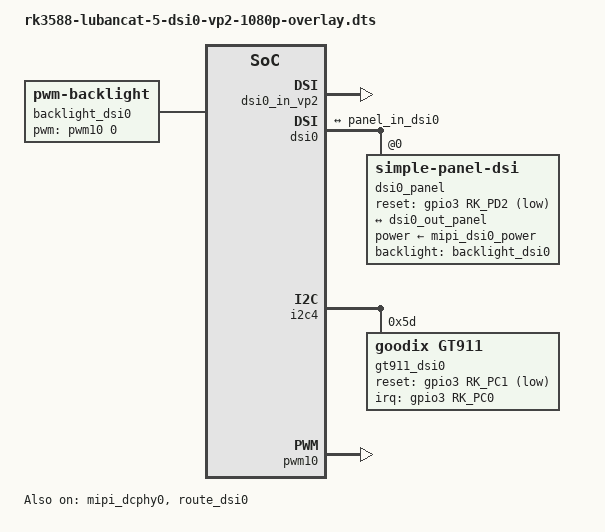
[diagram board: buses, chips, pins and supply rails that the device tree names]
/dts-v1/;
/plugin/;

#include <dt-bindings/gpio/gpio.h>
#include <dt-bindings/pinctrl/rockchip.h>
#include <dt-bindings/display/drm_mipi_dsi.h>
#include <dt-bindings/interrupt-controller/irq.h>

/ {
	fragment@0 {
		target = <&mipi_dcphy0>;

		__overlay__ {
			status = "okay";
		};
	};

	fragment@1 {
		target = <&route_dsi0>;

		__overlay__ {
			status = "okay";
			connect = <&vp2_out_dsi0>;
		};
	};

	fragment@2 {
		target = <&dsi0_in_vp2>;

		__overlay__ {
			status = "okay";
		};
	};


	fragment@3 {
		target = <&dsi0>;

		__overlay__ {
			status = "okay";
			#address-cells = <1>;
			#size-cells = <0>;

			dsi0_panel: panel@0 {
				status = "okay";
				compatible = "simple-panel-dsi";
				reg = <0>;
				backlight = <&backlight_dsi0>;
				power-supply = <&mipi_dsi0_power>;
				reset-gpios = <&gpio3 RK_PD2 GPIO_ACTIVE_LOW>;

				enable-delay-ms = <35>;
				prepare-delay-ms = <6>;
				reset-delay-ms = <10>;
				init-delay-ms = <50>;
				unprepare-delay-ms = <0>;
				disable-delay-ms = <20>;

				size,width = <74>;
				size,height = <133>;

				dsi,flags = <(MIPI_DSI_MODE_VIDEO | MIPI_DSI_MODE_VIDEO_BURST | MIPI_DSI_MODE_LPM | MIPI_DSI_MODE_NO_EOT_PACKET)>;
				dsi,format = <MIPI_DSI_FMT_RGB888>;
				dsi,lanes  = <4>;

				panel-init-sequence = [
					39 00 05 FF AA 55 A5 80
					15 00 02 6F 31
					15 00 02 FA 00
					39 00 05 FF AA 55 A5 00
					39 00 06 F0 55 AA 52 08 00
					15 00 02 B1 21
					39 00 03 B2 10 82
					39 00 03 B2 87 22
					39 00 04 B4 25 02 8C
					39 00 03 B5 0A 00
					39 00 04 B8 00 04 02
					39 00 0A B9 03 00 18 11 31 44 03 51 00
					39 00 03 BA 00 32
					39 00 03 BC 7F 00
					39 00 05 BD 00 B6 10 10
					39 00 03 C6 11 10
					39 00 06 F0 55 AA 52 08 01
					39 00 03 B1 11 11
					39 00 07 B2 0D 0D 0D 0D 0D 0D
					39 00 07 B3 19 23 19 23 19 23
					39 00 07 B6 15 14 15 14 15 14
					39 00 03 BC 5F 00
					39 00 03 BD 5F 00
					39 00 03 BE 00 DB
					15 00 02 CA 0F
					39 00 06 F0 55 AA 52 08 02
					39 00 0F B0 00 09 1B 28 33 3D 45 30 2D 32 31 47 56 56
					39 00 10 B1 4E 60 74 74 86 8E 9C 9C A5 AD B7 C2 CE DA FF
					39 00 0F B2 00 09 1B 28 33 3D 45 30 2D 32 31 47 56 56
					39 00 10 B3 4E 60 74 74 86 8E 9C 9C A5 AD B7 C2 CE DA FF
					39 00 0F B4 00 09 1B 28 33 3D 45 30 2D 32 31 47 56 56
					39 00 10 B5 4E 60 74 74 86 8E 9C 9C A5 AD B7 C2 CE DA FF
					39 00 0F B6 00 09 1B 28 33 3D 45 30 2D 32 31 47 56 56
					39 00 10 B7 4E 60 74 74 86 8E 9C 9C A5 AD B7 C2 CE DA FF
					39 00 0F B8 00 09 1B 28 33 3D 45 30 2D 32 31 47 56 56
					39 00 10 B9 4E 60 74 74 86 8E 9C 9C A5 AD B7 C2 CE DA FF
					39 00 0F BA 00 09 1B 28 33 3D 45 30 2D 32 31 47 56 56
					39 00 10 BB 4E 60 74 74 86 8E 9C 9C A5 AD B7 C2 CE DA FF
					39 00 06 F0 55 AA 52 08 03
					39 00 05 B0 00 00 00 00
					39 00 05 B1 03 00 00 03
					39 00 08 B2 00 00 64 00 64 05 02
					39 00 03 B4 00 08
					39 00 05 B5 12 28 06 06
					39 00 06 BA 31 00 00 00 03
					39 00 06 BB 31 00 00 00 03
					39 00 06 F0 55 AA 52 08 05
					39 00 04 B0 03 11 3F
					39 00 03 B2 06 60
					39 00 03 B3 10 33
					15 00 02 B4 26
					39 00 04 B5 06 20 00
					39 00 04 B6 86 E0 00
					39 00 06 BA 8E 00 00 A4 00
					39 00 06 BB 06 00 00 20 00
					39 00 06 BC 8E 00 00 A4 00
					39 00 06 BD 2E 00 00 A4 00
					39 00 06 BE 8E 00 00 A0 00
					39 00 06 BF 06 00 00 24 00
					15 00 02 C1 00
					39 00 03 C8 05 10
					39 00 03 C9 03 10
					39 00 04 D0 00 0A 02
					39 00 04 D1 00 0A 04
					15 00 02 EC 12
					15 00 02 ED 00
					39 00 03 EE 03 00
					39 00 06 B0 00 04 08 11 12
					39 00 06 B1 1F 15 16 1F 1F
					39 00 06 B2 1F 13 1F 1F 1F
					39 00 06 B3 1F 19 19 19 19
					39 00 06 B4 1B 1B 1B 1B 1D
					39 00 04 B5 1D 1D 1D
					39 00 06 B6 00 05 09 11 12
					39 00 06 B7 1F 15 16 1F 1F
					39 00 06 B8 1F 13 1F 1F 1F
					39 00 06 B9 1F 19 19 19 19
					39 00 06 BA 1B 1B 1B 1B 1D
					39 00 04 BB 1D 1D 1D
					39 00 06 C0 00 09 05 12 11
					39 00 06 C1 1F 15 16 1F 1F
					39 00 06 C2 1F 13 1F 1F 1F
					39 00 06 C3 1F 19 19 19 19
					39 00 06 C4 1B 1B 1B 1B 1D
					39 00 04 C5 1D 1D 1D
					39 00 06 C6 00 08 04 12 11
					39 00 06 C7 1F 15 16 1F 1F
					39 00 06 C8 1F 13 1F 1F 1F
					39 00 06 C9 1F 19 19 19 19
					39 00 06 CA 1B 1B 1B 1B 1D
					39 00 04 CB 1D 1D 1D
					39 00 04 D0 00 AA 0A
					15 00 02 35 00
					05 C8 01 11
					15 00 02 FF 00 //CMD page select
					15 00 02 34 00 //SET_TEAR_OFF
					15 00 02 35 00 //SET_TEAR_ON
					05 C8 01 29
				];

				panel-exit-sequence = [
					05 78 01 28
					05 00 01 10
				];

				disp0_timings0: display-timings {
					native-mode = <&dsi0_timing0>;
					dsi0_timing0: timing0 {
						clock-frequency = <230163000>;
						hactive = <1440>;
						vactive = <2560>;
						hsync-len = <2>;
						hback-porch = <26>;
						hfront-porch = <20>;
						vsync-len = <2>;
						vback-porch = <8>;
						vfront-porch = <8>;
						hsync-active = <0>;
						vsync-active = <0>;
						de-active = <0>;
						pixelclk-active = <0>;
					};
				};

				ports {
					#address-cells = <1>;
					#size-cells = <0>;
					port@0 {
						reg = <0>;
						panel_in_dsi0: endpoint {
							remote-endpoint = <&dsi0_out_panel>;
						};
					};
				};
			};

			ports {
				#address-cells = <1>;
				#size-cells = <0>;

				port@1 {
					reg = <1>;
					dsi0_out_panel: endpoint {
						remote-endpoint = <&panel_in_dsi0>;
					};
				};
			};
		};
	};

	fragment@4 {
		target = <&i2c4>;

		__overlay__ {
			status = "okay";
			#address-cells = <1>;
			#size-cells = <0>;
			pinctrl-names = "default";
			pinctrl-0 = <&i2c4m3_xfer>;

			gt911_dsi0: gt911@5d {
				status = "okay";
				compatible = "goodix,gt911";
				reg = <0x5d>;
				interrupt-parent = <&gpio3>;
				interrupts = <RK_PC0 IRQ_TYPE_LEVEL_LOW>;
				reset-gpios = <&gpio3 RK_PC1 GPIO_ACTIVE_LOW>;
				irq-gpios = <&gpio3 RK_PC0 GPIO_ACTIVE_HIGH>;
				touchscreen-inverted-x = <1>;
				touchscreen-inverted-y = <1>;
			};
		};
	};

	fragment@5 {
		target-path = "/";

		__overlay__ {
			backlight_dsi0: backlight-dsi0 {
				status = "okay";
				compatible = "pwm-backlight";
				pwms = <&pwm10 0 25000 0>;
				brightness-levels = <
				0  20  20  21  21  22  22  23
				23  24  24  25  25  26  26  27
				27  28  28  29  29  30  30  31
				31  32  32  33  33  34  34  35
				35  36  36  37  37  38  38  39
				40  41  42  43  44  45  46  47
				48  49  50  51  52  53  54  55
				56  57  58  59  60  61  62  63
				64  65  66  67  68  69  70  71
				72  73  74  75  76  77  78  79
				80  81  82  83  84  85  86  87
				88  89  90  91  92  93  94  95
				96  97  98  99 100 101 102 103
				104 105 106 107 108 109 110 111
				112 113 114 115 116 117 118 119
				120 121 122 123 124 125 126 127
				128 129 130 131 132 133 134 135
				136 137 138 139 140 141 142 143
				144 145 146 147 148 149 150 151
				152 153 154 155 156 157 158 159
				160 161 162 163 164 165 166 167
				168 169 170 171 172 173 174 175
				176 177 178 179 180 181 182 183
				184 185 186 187 188 189 190 191
				192 193 194 195 196 197 198 199
				200 201 202 203 204 205 206 207
				208 209 210 211 212 213 214 215
				216 217 218 219 220 221 222 223
				224 225 226 227 228 229 230 231
				232 233 234 235 236 237 238 239
				240 241 242 243 244 245 246 247
				248 249 250 251 252 253 254 255
				>;
				default-brightness-level = <200>;
			};
		};
	};

	fragment@6 {
		target = <&pwm10>;

		__overlay__ {
			pinctrl-0 = <&pwm10m2_pins>;
			status = "okay";
		};
	};
};
